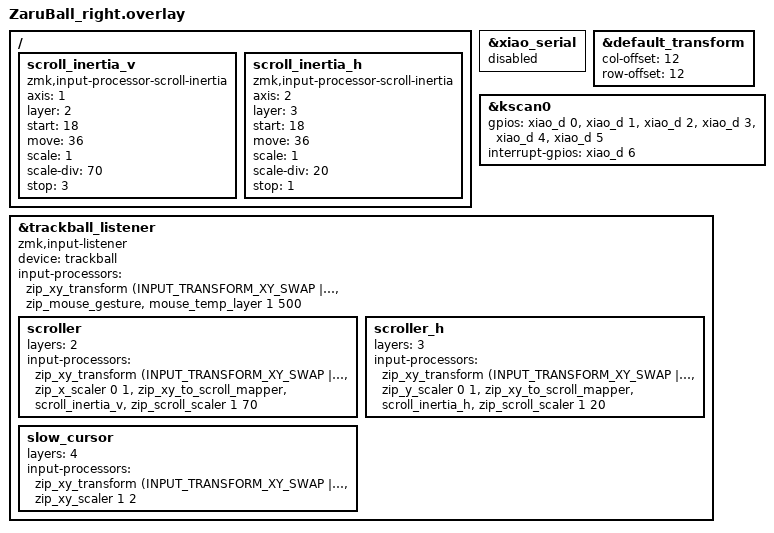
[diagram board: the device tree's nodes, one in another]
#include "ZaruBall.dtsi"
#include <dt-bindings/zmk/input_transform.h>

&xiao_serial { status = "disabled"; };

// matrix transformでのピン数オフセット
&default_transform { // Offset of 7 because the left side has 2 columns
    col-offset = <12>;
    row-offset = <12>;
};

&kscan0 {
    gpios
        = <&xiao_d 0 GPIO_ACTIVE_HIGH>//M1
        , <&xiao_d 1 GPIO_ACTIVE_HIGH>//M2
        , <&xiao_d 2 GPIO_ACTIVE_HIGH>//M3
        , <&xiao_d 3 GPIO_ACTIVE_HIGH>//M4
        , <&xiao_d 4 GPIO_ACTIVE_HIGH>//M5
        , <&xiao_d 5 GPIO_ACTIVE_HIGH>//M6
        ;
    interrupt-gpios = <&xiao_d 6 (GPIO_ACTIVE_HIGH | GPIO_PULL_DOWN)>;//IGPIO
};

// pmw-3610
&trackball_listener {
    status = "okay";
    compatible = "zmk,input-listener";
    device = <&trackball>;

    input-processors = <
                         &zip_xy_transform (INPUT_TRANSFORM_XY_SWAP | INPUT_TRANSFORM_Y_INVERT | INPUT_TRANSFORM_X_INVERT)
                         &zip_mouse_gesture
                         &mouse_temp_layer 1 500
    >;

    scroller {
        layers = <2>;
        input-processors = <
                            &zip_xy_transform (INPUT_TRANSFORM_XY_SWAP | INPUT_TRANSFORM_X_INVERT)
                            &zip_x_scaler 0 1
                            &zip_xy_to_scroll_mapper
                            &scroll_inertia_v
                            &zip_scroll_scaler 1 70
        >;
    };

    scroller_h {
        layers = <3>;
        input-processors = <
                            &zip_xy_transform (INPUT_TRANSFORM_XY_SWAP | INPUT_TRANSFORM_X_INVERT)
                            &zip_y_scaler 0 1
                            &zip_xy_to_scroll_mapper
                            &scroll_inertia_h
                            &zip_scroll_scaler 1 20
        >;
    };

    slow_cursor {
        layers = <4>;
        input-processors = <
                            &zip_xy_transform (INPUT_TRANSFORM_XY_SWAP | INPUT_TRANSFORM_Y_INVERT | INPUT_TRANSFORM_X_INVERT)
                            &zip_xy_scaler 1 2
        >;
    };
};

/ {
    scroll_inertia_v: scroll_inertia_v {
        compatible = "zmk,input-processor-scroll-inertia";
        #input-processor-cells = <0>;
        axis = <1>;
        layer = <2>;
        start = <18>;
        move = <36>;
        scale = <1>;
        scale-div = <70>;
        stop = <3>;
    };

    scroll_inertia_h: scroll_inertia_h {
        compatible = "zmk,input-processor-scroll-inertia";
        #input-processor-cells = <0>;
        axis = <2>;
        layer = <3>;
        start = <18>;
        move = <36>;
        scale = <1>;
        scale-div = <20>;
        stop = <1>;
    };
};
